VERSION ""

NS_ :

BS_:

BU_: DBG ECU

BO_ 512 BRAKE_CMD: 8 ECU
 SG_ Pedal_Voltage : 15|16@0+ (1,0) [0|5000] "mV"  DBG
 SG_ Pedal_Force : 31|8@0+ (1,0) [0|100] "%"  DBG

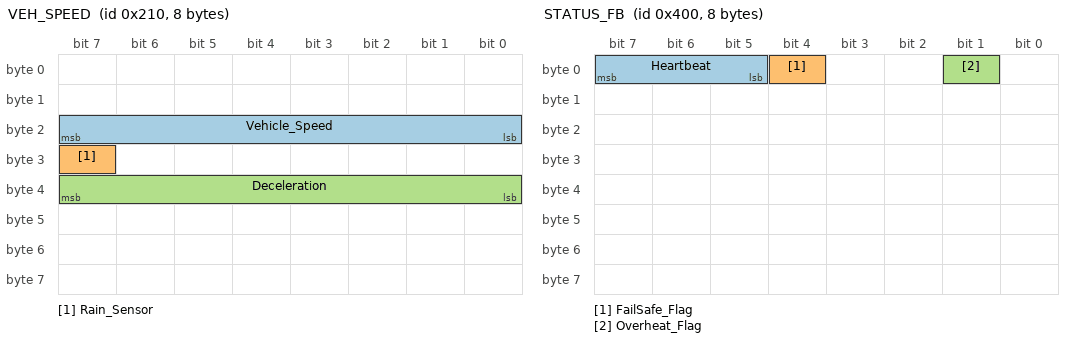
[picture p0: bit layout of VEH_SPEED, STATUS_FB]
BO_ 528 VEH_SPEED: 8 DBG
 SG_ Vehicle_Speed : 23|8@0+ (1,0) [0|255] "km/h"  ECU
 SG_ Rain_Sensor : 31|1@0+ (1,0) [0|1] ""  ECU
 SG_ Deceleration : 39|8@0+ (1,0) [0|255] "m/s2"  ECU

BO_ 768 PRESSURE_FB: 8 ECU
 SG_ Front_Pressure : 31|8@0+ (1,0) [0|250] "Bar"  DBG
 SG_ Rear_Pressure : 39|8@0+ (1,0) [0|250] "Bar"  DBG

BO_ 1024 STATUS_FB: 8 ECU
 SG_ Heartbeat : 7|3@0+ (1,0) [0|7] ""  DBG
 SG_ FailSafe_Flag : 4|1@0+ (1,0) [0|1] ""  DBG
 SG_ Overheat_Flag : 1|1@0+ (1,0) [0|1] ""  DBG

BO_ 544 BRAKE_TEMP: 8 DBG
 SG_ Brake_Temperature : 7|8@0+ (1,0) [0|255] "C"  ECU

CM_ BO_ 512 "Brake command from Driver/ADAS";
CM_ SG_ 512 Pedal_Voltage "0.5V to 4.5V range";
CM_ BO_ 768 "Feedback from Hydraulic Control Unit";
